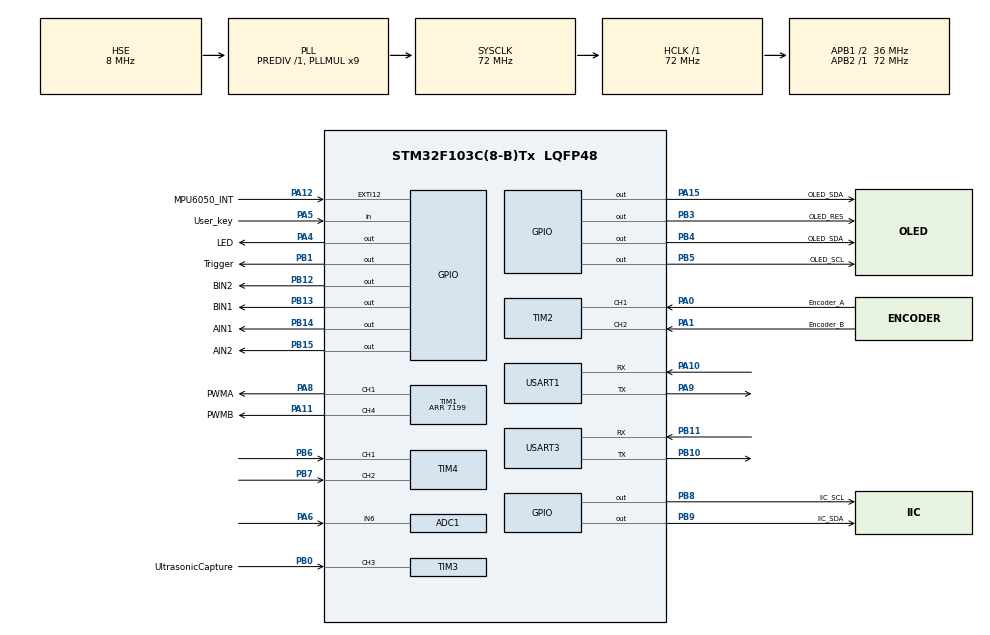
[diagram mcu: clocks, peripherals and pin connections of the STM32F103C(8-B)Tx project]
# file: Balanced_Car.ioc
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ADC1.Channel-0\#ChannelRegularConversion=ADC_CHANNEL_6
ADC1.NbrOfConversionFlag=1
ADC1.Rank-0\#ChannelRegularConversion=1
ADC1.SamplingTime-0\#ChannelRegularConversion=ADC_SAMPLETIME_1CYCLE_5
ADC1.master=1
Mcu.Family=STM32F1
Mcu.Name=STM32F103C(8-B)Tx
Mcu.Package=LQFP48
NVIC.EXTI15_10_IRQn=true\:2\:0\:true\:false\:true\:true\:true\:true
NVIC.PriorityGroup=NVIC_PRIORITYGROUP_4
NVIC.TIM3_IRQn=true\:1\:0\:true\:false\:true\:true\:true\:true
NVIC.USART3_IRQn=true\:1\:0\:true\:false\:true\:true\:true\:true
PA0-WKUP.GPIO_Label=Encoder_A
PA0-WKUP.Signal=S_TIM2_CH1_ETR
PA1.GPIO_Label=Encoder_B
PA1.Signal=S_TIM2_CH2
PA10.Mode=Asynchronous
PA10.Signal=USART1_RX
PA11.GPIO_Label=PWMB
PA11.Signal=S_TIM1_CH4
PA12.GPIO_Label=MPU6050_INT
PA12.Signal=GPXTI12
PA13.Mode=Serial_Wire
PA13.Signal=SYS_JTMS-SWDIO
PA14.Mode=Serial_Wire
PA14.Signal=SYS_JTCK-SWCLK
PA15.GPIO_Label=OLED_SDA
PA15.GPIO_Speed=GPIO_SPEED_FREQ_HIGH
PA15.PinState=GPIO_PIN_SET
PA15.Signal=GPIO_Output
PA4.GPIO_Label=LED
PA4.PinState=GPIO_PIN_SET
PA4.Signal=GPIO_Output
PA5.GPIO_Label=User_key
PA5.GPIO_PuPd=GPIO_PULLUP
PA5.Signal=GPIO_Input
PA6.Signal=ADCx_IN6
PA8.GPIO_Label=PWMA
PA8.Signal=S_TIM1_CH1
PA9.Mode=Asynchronous
PA9.Signal=USART1_TX
PB0.GPIO_Label=UltrasonicCapture
PB0.Signal=S_TIM3_CH3
PB1.GPIO_Label=Trigger
PB1.GPIO_Speed=GPIO_SPEED_FREQ_HIGH
PB1.PinState=GPIO_PIN_SET
PB1.Signal=GPIO_Output
PB10.Mode=Asynchronous
PB10.Signal=USART3_TX
PB11.Mode=Asynchronous
PB11.Signal=USART3_RX
PB12.GPIO_Label=BIN2
PB12.GPIO_Speed=GPIO_SPEED_FREQ_HIGH
PB12.PinState=GPIO_PIN_SET
PB12.Signal=GPIO_Output
PB13.GPIO_Label=BIN1
PB13.GPIO_Speed=GPIO_SPEED_FREQ_HIGH
PB13.PinState=GPIO_PIN_SET
PB13.Signal=GPIO_Output
PB14.GPIO_Label=AIN1
PB14.GPIO_Speed=GPIO_SPEED_FREQ_HIGH
PB14.PinState=GPIO_PIN_SET
PB14.Signal=GPIO_Output
PB15.GPIO_Label=AIN2
PB15.PinState=GPIO_PIN_RESET
PB15.Signal=GPIO_Output
PB3.GPIO_Label=OLED_RES
PB3.GPIO_PuPd=GPIO_NOPULL
PB3.GPIO_Speed=GPIO_SPEED_FREQ_HIGH
PB3.PinState=GPIO_PIN_SET
PB3.Signal=GPIO_Output
PB4.GPIO_Label=OLED_SDA
PB4.GPIO_Speed=GPIO_SPEED_FREQ_HIGH
PB4.PinState=GPIO_PIN_SET
PB4.Signal=GPIO_Output
PB5.GPIO_Label=OLED_SCL
PB5.GPIO_ModeDefaultOutputPP=GPIO_MODE_OUTPUT_PP
PB5.GPIO_Speed=GPIO_SPEED_FREQ_HIGH
PB5.PinState=GPIO_PIN_SET
PB5.Signal=GPIO_Output
PB6.Signal=S_TIM4_CH1
PB7.Signal=S_TIM4_CH2
PB8.GPIO_Label=IIC_SCL
PB8.GPIO_Speed=GPIO_SPEED_FREQ_HIGH
PB8.PinState=GPIO_PIN_SET
PB8.Signal=GPIO_Output
PB9.GPIO_Label=IIC_SDA
PB9.GPIO_Speed=GPIO_SPEED_FREQ_HIGH
PB9.PinState=GPIO_PIN_SET
PB9.Signal=GPIO_Output
PD0-OSC_IN.Mode=HSE-External-Oscillator
PD0-OSC_IN.Signal=RCC_OSC_IN
PD1-OSC_OUT.Mode=HSE-External-Oscillator
PD1-OSC_OUT.Signal=RCC_OSC_OUT
ProjectManager.HeapSize=0x200
ProjectManager.StackSize=0x400
ProjectManager.TargetToolchain=MDK-ARM V5.32
RCC.ADCPresc=RCC_ADCPCLK2_DIV6
RCC.AHBFreq_Value=72000000
RCC.APB1CLKDivider=RCC_HCLK_DIV2
RCC.APB1Freq_Value=36000000
RCC.APB1TimFreq_Value=72000000
RCC.APB2Freq_Value=72000000
RCC.APB2TimFreq_Value=72000000
RCC.HCLKFreq_Value=72000000
RCC.PLLMUL=RCC_PLL_MUL9
RCC.PLLSourceVirtual=RCC_PLLSOURCE_HSE
RCC.SYSCLKFreq_VALUE=72000000
RCC.SYSCLKSource=RCC_SYSCLKSOURCE_PLLCLK
RCC.USBFreq_Value=72000000
SH.ADCx_IN6.0=ADC1_IN6,IN6
SH.S_TIM1_CH1.0=TIM1_CH1,PWM Generation1 CH1
SH.S_TIM1_CH4.0=TIM1_CH4,PWM Generation4 CH4
SH.S_TIM2_CH1_ETR.0=TIM2_CH1,Encoder_Interface
SH.S_TIM2_CH2.0=TIM2_CH2,Encoder_Interface
SH.S_TIM3_CH3.0=TIM3_CH3,Input_Capture3_from_TI3
SH.S_TIM4_CH1.0=TIM4_CH1,Encoder_Interface
SH.S_TIM4_CH2.0=TIM4_CH2,Encoder_Interface
TIM1.Channel-PWM\ Generation1\ CH1=TIM_CHANNEL_1
TIM1.Channel-PWM\ Generation4\ CH4=TIM_CHANNEL_4
TIM1.Period=7199
TIM2.EncoderMode=TIM_ENCODERMODE_TI12
TIM2.IC1Filter=10
TIM2.IC2Filter=10
TIM3.Channel-Input_Capture3_from_TI3=TIM_CHANNEL_3
TIM3.Prescaler=71
USART1.VirtualMode=VM_ASYNC
USART3.VirtualMode=VM_ASYNC
VP_TIM3_VS_ClockSourceINT.Mode=Internal
board=custom

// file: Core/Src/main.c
/* USER CODE BEGIN Header */
/**
  ******************************************************************************
  * @file           : main.c
  * @brief          : Main program body
  ******************************************************************************
  * @attention
  *
  * Copyright (c) 2024 STMicroelectronics.
  * All rights reserved.
  *
  * This software is licensed under terms that can be found in the LICENSE file
  * in the root directory of this software component.
  * If no LICENSE file comes with this software, it is provided AS-IS.
  *
  ******************************************************************************
  */
/* USER CODE END Header */
#include "main.h"
#include "adc.h"
#include "tim.h"
#include "usart.h"
#include "gpio.h"

/* USER CODE BEGIN PV */
float Angle_Balance,Gyro_Balance,Gyro_Turn;     						 //平衡倾角 平衡陀螺仪 转向陀螺仪
int Temperature;
float Acceleration_Z;                       //Z轴加速度计
/* USER CODE END PV */

void SystemClock_Config(void);

int main(void)
{

  /* MCU Configuration--------------------------------------------------------*/

  /* Reset of all peripherals, Initializes the Flash interface and the Systick. */
  HAL_Init();

  /* Configure the system clock */
  SystemClock_Config();

  /* Initialize all configured peripherals */
  MX_GPIO_Init();
  MX_ADC1_Init();
  MX_TIM1_Init();
  MX_TIM2_Init();
  MX_TIM3_Init();
  MX_TIM4_Init();
  MX_USART1_UART_Init();
  MX_USART3_UART_Init();
  /* USER CODE BEGIN 2 */
	HAL_NVIC_DisableIRQ(EXTI15_10_IRQn); //先关闭配置的外部中断，防止初始化过程中进入中断
  delay_init(); 						//释放SysTick，使用DWT作为HAL库时钟
  MPU6050_initialize();           		//MPU6050初始化
  DMP_Init();                     		//初始化DMP
  /* USER CODE END 2 */

  /* Infinite loop */
  while (1)
  {

  }
}

void SystemClock_Config(void)
{
  RCC_OscInitTypeDef RCC_OscInitStruct = {0};
  RCC_ClkInitTypeDef RCC_ClkInitStruct = {0};
  RCC_PeriphCLKInitTypeDef PeriphClkInit = {0};

  /** Initializes the RCC Oscillators according to the specified parameters
  * in the RCC_OscInitTypeDef structure.
  */
  RCC_OscInitStruct.OscillatorType = RCC_OSCILLATORTYPE_HSE;
  RCC_OscInitStruct.HSEState = RCC_HSE_ON;
  RCC_OscInitStruct.HSEPredivValue = RCC_HSE_PREDIV_DIV1;
  RCC_OscInitStruct.HSIState = RCC_HSI_ON;
  RCC_OscInitStruct.PLL.PLLState = RCC_PLL_ON;
  RCC_OscInitStruct.PLL.PLLSource = RCC_PLLSOURCE_HSE;
  RCC_OscInitStruct.PLL.PLLMUL = RCC_PLL_MUL9;
  if (HAL_RCC_OscConfig(&RCC_OscInitStruct) != HAL_OK)
  {
    Error_Handler();
  }

  /** Initializes the CPU, AHB and APB buses clocks
  */
  RCC_ClkInitStruct.ClockType = RCC_CLOCKTYPE_HCLK|RCC_CLOCKTYPE_SYSCLK
                              |RCC_CLOCKTYPE_PCLK1|RCC_CLOCKTYPE_PCLK2;
  RCC_ClkInitStruct.SYSCLKSource = RCC_SYSCLKSOURCE_PLLCLK;
  RCC_ClkInitStruct.AHBCLKDivider = RCC_SYSCLK_DIV1;
  RCC_ClkInitStruct.APB1CLKDivider = RCC_HCLK_DIV2;
  RCC_ClkInitStruct.APB2CLKDivider = RCC_HCLK_DIV1;

  if (HAL_RCC_ClockConfig(&RCC_ClkInitStruct, FLASH_LATENCY_2) != HAL_OK)
  {
    Error_Handler();
  }
  PeriphClkInit.PeriphClockSelection = RCC_PERIPHCLK_ADC;
  PeriphClkInit.AdcClockSelection = RCC_ADCPCLK2_DIV6;
  if (HAL_RCCEx_PeriphCLKConfig(&PeriphClkInit) != HAL_OK)
  {
    Error_Handler();
  }
}

void Error_Handler(void)
{
  __disable_irq();
  while (1)
  {
  }
}
